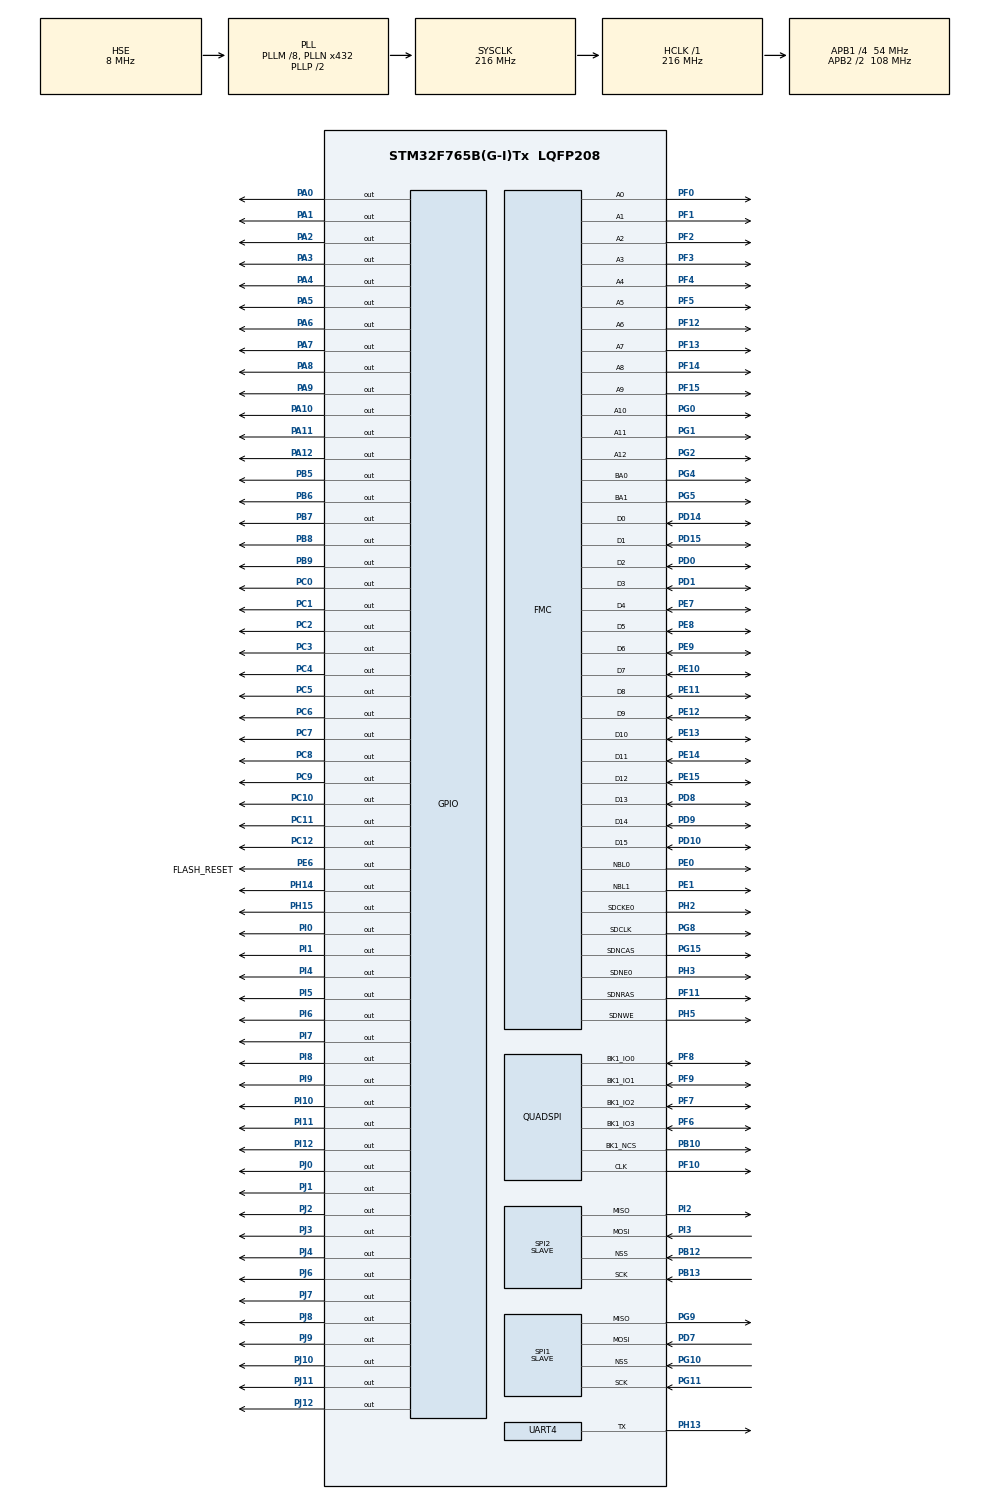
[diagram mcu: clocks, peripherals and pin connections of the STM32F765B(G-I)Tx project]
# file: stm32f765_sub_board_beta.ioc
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CORTEX_M7.ART_ACCLERATOR_ENABLE=1
CORTEX_M7.CPU_DCache=Enabled
CORTEX_M7.CPU_ICache=Enabled
CORTEX_M7.PREFETCH_ENABLE=1
FMC.CASLatency1=FMC_SDRAM_CAS_LATENCY_3
FMC.ColumnBitsNumber1=FMC_SDRAM_COLUMN_BITS_NUM_9
FMC.ExitSelfRefreshDelay1=8
FMC.LoadToActiveDelay1=2
FMC.RCDDelay1=2
FMC.RPDelay1=2
FMC.RPDelay2=2
FMC.ReadBurst1=FMC_SDRAM_RBURST_ENABLE
FMC.ReadBurst2=FMC_SDRAM_RBURST_ENABLE
FMC.ReadPipeDelay1=FMC_SDRAM_RPIPE_DELAY_1
FMC.ReadPipeDelay2=FMC_SDRAM_RPIPE_DELAY_1
FMC.RowCycleDelay1=6
FMC.RowCycleDelay2=6
FMC.SDClockPeriod1=FMC_SDRAM_CLOCK_PERIOD_2
FMC.SDClockPeriod2=FMC_SDRAM_CLOCK_PERIOD_2
FMC.SelfRefreshTime1=6
FMC.WriteProtection1=FMC_SDRAM_WRITE_PROTECTION_DISABLE
FMC.WriteRecoveryTime1=4
Mcu.Family=STM32F7
Mcu.Name=STM32F765B(G-I)Tx
Mcu.Package=LQFP208
NVIC.PriorityGroup=NVIC_PRIORITYGROUP_4
NVIC.SPI1_IRQn=true\:4\:0\:true\:true\:true\:3
NVIC.SPI2_IRQn=true\:2\:0\:true\:true\:true\:1
NVIC.TIM8_TRG_COM_TIM14_IRQn=true\:14\:0\:true\:true\:true\:4
NVIC.UART4_IRQn=true\:6\:0\:true\:true\:true\:2
PA0/WKUP.GPIO_ModeDefaultOutputPP=GPIO_MODE_OUTPUT_PP
PA0/WKUP.GPIO_PuPd=GPIO_NOPULL
PA0/WKUP.GPIO_Speed=GPIO_SPEED_FREQ_VERY_HIGH
PA0/WKUP.PinState=GPIO_PIN_RESET
PA0/WKUP.Signal=GPIO_Output
PA1.GPIO_ModeDefaultOutputPP=GPIO_MODE_OUTPUT_PP
PA1.GPIO_PuPd=GPIO_NOPULL
PA1.GPIO_Speed=GPIO_SPEED_FREQ_VERY_HIGH
PA1.PinState=GPIO_PIN_RESET
PA1.Signal=GPIO_Output
PA10.GPIO_ModeDefaultOutputPP=GPIO_MODE_OUTPUT_PP
PA10.GPIO_PuPd=GPIO_NOPULL
PA10.GPIO_Speed=GPIO_SPEED_FREQ_VERY_HIGH
PA10.PinState=GPIO_PIN_RESET
PA10.Signal=GPIO_Output
PA11.GPIO_ModeDefaultOutputPP=GPIO_MODE_OUTPUT_PP
PA11.GPIO_PuPd=GPIO_NOPULL
PA11.GPIO_Speed=GPIO_SPEED_FREQ_VERY_HIGH
PA11.PinState=GPIO_PIN_RESET
PA11.Signal=GPIO_Output
PA12.GPIO_ModeDefaultOutputPP=GPIO_MODE_OUTPUT_PP
PA12.GPIO_PuPd=GPIO_NOPULL
PA12.GPIO_Speed=GPIO_SPEED_FREQ_VERY_HIGH
PA12.PinState=GPIO_PIN_RESET
PA12.Signal=GPIO_Output
PA2.GPIO_ModeDefaultOutputPP=GPIO_MODE_OUTPUT_PP
PA2.GPIO_PuPd=GPIO_NOPULL
PA2.GPIO_Speed=GPIO_SPEED_FREQ_VERY_HIGH
PA2.PinState=GPIO_PIN_RESET
PA2.Signal=GPIO_Output
PA3.GPIO_ModeDefaultOutputPP=GPIO_MODE_OUTPUT_PP
PA3.GPIO_PuPd=GPIO_NOPULL
PA3.GPIO_Speed=GPIO_SPEED_FREQ_VERY_HIGH
PA3.PinState=GPIO_PIN_RESET
PA3.Signal=GPIO_Output
PA4.GPIO_ModeDefaultOutputPP=GPIO_MODE_OUTPUT_PP
PA4.GPIO_PuPd=GPIO_NOPULL
PA4.GPIO_Speed=GPIO_SPEED_FREQ_VERY_HIGH
PA4.PinState=GPIO_PIN_RESET
PA4.Signal=GPIO_Output
PA5.GPIO_ModeDefaultOutputPP=GPIO_MODE_OUTPUT_PP
PA5.GPIO_PuPd=GPIO_NOPULL
PA5.GPIO_Speed=GPIO_SPEED_FREQ_VERY_HIGH
PA5.PinState=GPIO_PIN_RESET
PA5.Signal=GPIO_Output
PA6.GPIO_ModeDefaultOutputPP=GPIO_MODE_OUTPUT_PP
PA6.GPIO_PuPd=GPIO_NOPULL
PA6.GPIO_Speed=GPIO_SPEED_FREQ_VERY_HIGH
PA6.PinState=GPIO_PIN_RESET
PA6.Signal=GPIO_Output
PA7.GPIO_ModeDefaultOutputPP=GPIO_MODE_OUTPUT_PP
PA7.GPIO_PuPd=GPIO_NOPULL
PA7.GPIO_Speed=GPIO_SPEED_FREQ_VERY_HIGH
PA7.PinState=GPIO_PIN_RESET
PA7.Signal=GPIO_Output
PA8.GPIO_ModeDefaultOutputPP=GPIO_MODE_OUTPUT_PP
PA8.GPIO_PuPd=GPIO_NOPULL
PA8.GPIO_Speed=GPIO_SPEED_FREQ_VERY_HIGH
PA8.PinState=GPIO_PIN_RESET
PA8.Signal=GPIO_Output
PA9.GPIO_ModeDefaultOutputPP=GPIO_MODE_OUTPUT_PP
PA9.GPIO_PuPd=GPIO_NOPULL
PA9.GPIO_Speed=GPIO_SPEED_FREQ_VERY_HIGH
PA9.PinState=GPIO_PIN_RESET
PA9.Signal=GPIO_Output
PB10.Mode=Single Bank 1
PB10.Signal=QUADSPI_BK1_NCS
PB12.Mode=NSS_Signal_Hard_Input
PB12.Signal=SPI2_NSS
PB13.Mode=Full_Duplex_Slave
PB13.Signal=SPI2_SCK
PB5.GPIO_ModeDefaultOutputPP=GPIO_MODE_OUTPUT_PP
PB5.GPIO_PuPd=GPIO_NOPULL
PB5.GPIO_Speed=GPIO_SPEED_FREQ_VERY_HIGH
PB5.PinState=GPIO_PIN_RESET
PB5.Signal=GPIO_Output
PB6.GPIO_FM6=SYSCFG_PMC_I2C_PB6_FMP
PB6.GPIO_ModeDefaultOutputPP=GPIO_MODE_OUTPUT_PP
PB6.GPIO_PuPd=GPIO_NOPULL
PB6.GPIO_Speed=GPIO_SPEED_FREQ_VERY_HIGH
PB6.PinState=GPIO_PIN_RESET
PB6.Signal=GPIO_Output
PB7.GPIO_FM7=SYSCFG_PMC_I2C_PB7_FMP
PB7.GPIO_ModeDefaultOutputPP=GPIO_MODE_OUTPUT_PP
PB7.GPIO_PuPd=GPIO_NOPULL
PB7.GPIO_Speed=GPIO_SPEED_FREQ_VERY_HIGH
PB7.PinState=GPIO_PIN_RESET
PB7.Signal=GPIO_Output
PB8.GPIO_FM8=SYSCFG_PMC_I2C_PB8_FMP
PB8.GPIO_ModeDefaultOutputPP=GPIO_MODE_OUTPUT_PP
PB8.GPIO_PuPd=GPIO_NOPULL
PB8.GPIO_Speed=GPIO_SPEED_FREQ_VERY_HIGH
PB8.PinState=GPIO_PIN_RESET
PB8.Signal=GPIO_Output
PB9.GPIO_FM9=SYSCFG_PMC_I2C_PB9_FMP
PB9.GPIO_ModeDefaultOutputPP=GPIO_MODE_OUTPUT_PP
PB9.GPIO_PuPd=GPIO_NOPULL
PB9.GPIO_Speed=GPIO_SPEED_FREQ_VERY_HIGH
PB9.PinState=GPIO_PIN_RESET
PB9.Signal=GPIO_Output
PC0.GPIO_ModeDefaultOutputPP=GPIO_MODE_OUTPUT_PP
PC0.GPIO_PuPd=GPIO_NOPULL
PC0.GPIO_Speed=GPIO_SPEED_FREQ_VERY_HIGH
PC0.PinState=GPIO_PIN_RESET
PC0.Signal=GPIO_Output
PC1.GPIO_ModeDefaultOutputPP=GPIO_MODE_OUTPUT_PP
PC1.GPIO_PuPd=GPIO_NOPULL
PC1.GPIO_Speed=GPIO_SPEED_FREQ_VERY_HIGH
PC1.PinState=GPIO_PIN_RESET
PC1.Signal=GPIO_Output
PC10.GPIO_ModeDefaultOutputPP=GPIO_MODE_OUTPUT_PP
PC10.GPIO_PuPd=GPIO_NOPULL
PC10.GPIO_Speed=GPIO_SPEED_FREQ_VERY_HIGH
PC10.PinState=GPIO_PIN_RESET
PC10.Signal=GPIO_Output
PC11.GPIO_ModeDefaultOutputPP=GPIO_MODE_OUTPUT_PP
PC11.GPIO_PuPd=GPIO_NOPULL
PC11.GPIO_Speed=GPIO_SPEED_FREQ_VERY_HIGH
PC11.PinState=GPIO_PIN_RESET
PC11.Signal=GPIO_Output
PC12.GPIO_ModeDefaultOutputPP=GPIO_MODE_OUTPUT_PP
PC12.GPIO_PuPd=GPIO_NOPULL
PC12.GPIO_Speed=GPIO_SPEED_FREQ_VERY_HIGH
PC12.PinState=GPIO_PIN_RESET
PC12.Signal=GPIO_Output
PC2.GPIO_ModeDefaultOutputPP=GPIO_MODE_OUTPUT_PP
PC2.GPIO_PuPd=GPIO_NOPULL
PC2.GPIO_Speed=GPIO_SPEED_FREQ_VERY_HIGH
PC2.PinState=GPIO_PIN_RESET
PC2.Signal=GPIO_Output
PC3.GPIO_ModeDefaultOutputPP=GPIO_MODE_OUTPUT_PP
PC3.GPIO_PuPd=GPIO_NOPULL
PC3.GPIO_Speed=GPIO_SPEED_FREQ_VERY_HIGH
PC3.PinState=GPIO_PIN_RESET
PC3.Signal=GPIO_Output
PC4.GPIO_ModeDefaultOutputPP=GPIO_MODE_OUTPUT_PP
PC4.GPIO_PuPd=GPIO_NOPULL
PC4.GPIO_Speed=GPIO_SPEED_FREQ_VERY_HIGH
PC4.PinState=GPIO_PIN_RESET
PC4.Signal=GPIO_Output
PC5.GPIO_ModeDefaultOutputPP=GPIO_MODE_OUTPUT_PP
PC5.GPIO_PuPd=GPIO_NOPULL
PC5.GPIO_Speed=GPIO_SPEED_FREQ_VERY_HIGH
PC5.PinState=GPIO_PIN_RESET
PC5.Signal=GPIO_Output
PC6.GPIO_ModeDefaultOutputPP=GPIO_MODE_OUTPUT_PP
PC6.GPIO_PuPd=GPIO_NOPULL
PC6.GPIO_Speed=GPIO_SPEED_FREQ_VERY_HIGH
PC6.PinState=GPIO_PIN_RESET
PC6.Signal=GPIO_Output
PC7.GPIO_ModeDefaultOutputPP=GPIO_MODE_OUTPUT_PP
PC7.GPIO_PuPd=GPIO_NOPULL
PC7.GPIO_Speed=GPIO_SPEED_FREQ_VERY_HIGH
PC7.PinState=GPIO_PIN_RESET
PC7.Signal=GPIO_Output
PC8.GPIO_ModeDefaultOutputPP=GPIO_MODE_OUTPUT_PP
PC8.GPIO_PuPd=GPIO_NOPULL
PC8.GPIO_Speed=GPIO_SPEED_FREQ_VERY_HIGH
PC8.PinState=GPIO_PIN_RESET
PC8.Signal=GPIO_Output
PC9.GPIO_ModeDefaultOutputPP=GPIO_MODE_OUTPUT_PP
PC9.GPIO_PuPd=GPIO_NOPULL
PC9.GPIO_Speed=GPIO_SPEED_FREQ_VERY_HIGH
PC9.PinState=GPIO_PIN_RESET
PC9.Signal=GPIO_Output
PD0.Signal=FMC_D2_DA2
PD1.Signal=FMC_D3_DA3
PD10.Signal=FMC_D15_DA15
PD14.Signal=FMC_D0_DA0
PD15.Signal=FMC_D1_DA1
PD7.Mode=Full_Duplex_Slave
PD7.Signal=SPI1_MOSI
PD8.Signal=FMC_D13_DA13
PD9.Signal=FMC_D14_DA14
PE0.Signal=FMC_NBL0
PE1.Signal=FMC_NBL1
PE10.Signal=FMC_D7_DA7
PE11.Signal=FMC_D8_DA8
PE12.Signal=FMC_D9_DA9
PE13.Signal=FMC_D10_DA10
PE14.Signal=FMC_D11_DA11
PE15.Signal=FMC_D12_DA12
PE6.GPIO_Label=FLASH_RESET
PE6.GPIO_ModeDefaultOutputPP=GPIO_MODE_OUTPUT_PP
PE6.GPIO_PuPd=GPIO_NOPULL
PE6.GPIO_Speed=GPIO_SPEED_FREQ_VERY_HIGH
PE6.PinState=GPIO_PIN_RESET
PE6.Signal=GPIO_Output
PE7.Signal=FMC_D4_DA4
PE8.Signal=FMC_D5_DA5
PE9.Signal=FMC_D6_DA6
PF0.Signal=FMC_A0
PF1.Signal=FMC_A1
PF10.Mode=Single Bank 1
PF10.Signal=QUADSPI_CLK
PF11.Signal=FMC_SDNRAS
PF12.Signal=FMC_A6
PF13.Signal=FMC_A7
PF14.Signal=FMC_A8
PF15.Signal=FMC_A9
PF2.Signal=FMC_A2
PF3.Signal=FMC_A3
PF4.Signal=FMC_A4
PF5.Signal=FMC_A5
PF6.Mode=Single Bank 1
PF6.Signal=QUADSPI_BK1_IO3
PF7.Mode=Single Bank 1
PF7.Signal=QUADSPI_BK1_IO2
PF8.Mode=Single Bank 1
PF8.Signal=QUADSPI_BK1_IO0
PF9.Mode=Single Bank 1
PF9.Signal=QUADSPI_BK1_IO1
PG0.Signal=FMC_A10
PG1.Signal=FMC_A11
PG10.Mode=NSS_Signal_Hard_Input
PG10.Signal=SPI1_NSS
PG11.Mode=Full_Duplex_Slave
PG11.Signal=SPI1_SCK
PG15.Signal=FMC_SDNCAS
PG2.Signal=FMC_A12
PG4.Signal=FMC_A14_BA0
PG5.Signal=FMC_A15_BA1
PG8.Signal=FMC_SDCLK
PG9.Mode=Full_Duplex_Slave
PG9.Signal=SPI1_MISO
PH0/OSC_IN.Mode=HSE-External-Oscillator
PH0/OSC_IN.Signal=RCC_OSC_IN
PH1/OSC_OUT.Mode=HSE-External-Oscillator
PH1/OSC_OUT.Signal=RCC_OSC_OUT
PH13.Mode=Half_duplex(single_wire_mode)
PH13.Signal=UART4_TX
PH14.GPIO_ModeDefaultOutputPP=GPIO_MODE_OUTPUT_PP
PH14.GPIO_PuPd=GPIO_NOPULL
PH14.GPIO_Speed=GPIO_SPEED_FREQ_VERY_HIGH
PH14.PinState=GPIO_PIN_RESET
PH14.Signal=GPIO_Output
PH15.GPIO_ModeDefaultOutputPP=GPIO_MODE_OUTPUT_PP
PH15.GPIO_PuPd=GPIO_NOPULL
PH15.GPIO_Speed=GPIO_SPEED_FREQ_VERY_HIGH
PH15.PinState=GPIO_PIN_RESET
PH15.Signal=GPIO_Output
PH2.Mode=SdramChipSelect1_1
PH2.Signal=FMC_SDCKE0
PH3.Mode=SdramChipSelect1_1
PH3.Signal=FMC_SDNE0
PH5.Signal=FMC_SDNWE
PI0.GPIO_ModeDefaultOutputPP=GPIO_MODE_OUTPUT_PP
PI0.GPIO_PuPd=GPIO_NOPULL
PI0.GPIO_Speed=GPIO_SPEED_FREQ_VERY_HIGH
PI0.PinState=GPIO_PIN_RESET
PI0.Signal=GPIO_Output
PI1.GPIO_ModeDefaultOutputPP=GPIO_MODE_OUTPUT_PP
PI1.GPIO_PuPd=GPIO_NOPULL
PI1.GPIO_Speed=GPIO_SPEED_FREQ_VERY_HIGH
PI1.PinState=GPIO_PIN_RESET
PI1.Signal=GPIO_Output
PI10.GPIO_ModeDefaultOutputPP=GPIO_MODE_OUTPUT_PP
PI10.GPIO_PuPd=GPIO_NOPULL
PI10.GPIO_Speed=GPIO_SPEED_FREQ_VERY_HIGH
PI10.PinState=GPIO_PIN_RESET
PI10.Signal=GPIO_Output
PI11.GPIO_ModeDefaultOutputPP=GPIO_MODE_OUTPUT_PP
PI11.GPIO_PuPd=GPIO_NOPULL
PI11.GPIO_Speed=GPIO_SPEED_FREQ_VERY_HIGH
PI11.PinState=GPIO_PIN_RESET
PI11.Signal=GPIO_Output
PI12.GPIO_ModeDefaultOutputPP=GPIO_MODE_OUTPUT_PP
PI12.GPIO_PuPd=GPIO_NOPULL
PI12.GPIO_Speed=GPIO_SPEED_FREQ_VERY_HIGH
PI12.PinState=GPIO_PIN_RESET
PI12.Signal=GPIO_Output
PI2.Mode=Full_Duplex_Slave
PI2.Signal=SPI2_MISO
PI3.Mode=Full_Duplex_Slave
PI3.Signal=SPI2_MOSI
PI4.GPIO_ModeDefaultOutputPP=GPIO_MODE_OUTPUT_PP
PI4.GPIO_PuPd=GPIO_NOPULL
PI4.GPIO_Speed=GPIO_SPEED_FREQ_VERY_HIGH
PI4.PinState=GPIO_PIN_RESET
PI4.Signal=GPIO_Output
PI5.GPIO_ModeDefaultOutputPP=GPIO_MODE_OUTPUT_PP
PI5.GPIO_PuPd=GPIO_NOPULL
PI5.GPIO_Speed=GPIO_SPEED_FREQ_VERY_HIGH
PI5.PinState=GPIO_PIN_RESET
PI5.Signal=GPIO_Output
PI6.GPIO_ModeDefaultOutputPP=GPIO_MODE_OUTPUT_PP
PI6.GPIO_PuPd=GPIO_NOPULL
PI6.GPIO_Speed=GPIO_SPEED_FREQ_VERY_HIGH
PI6.PinState=GPIO_PIN_RESET
PI6.Signal=GPIO_Output
PI7.GPIO_ModeDefaultOutputPP=GPIO_MODE_OUTPUT_PP
PI7.GPIO_PuPd=GPIO_NOPULL
PI7.GPIO_Speed=GPIO_SPEED_FREQ_VERY_HIGH
PI7.PinState=GPIO_PIN_RESET
PI7.Signal=GPIO_Output
PI8.GPIO_ModeDefaultOutputPP=GPIO_MODE_OUTPUT_PP
PI8.GPIO_PuPd=GPIO_NOPULL
PI8.GPIO_Speed=GPIO_SPEED_FREQ_LOW
PI8.PinState=GPIO_PIN_RESET
PI8.Signal=GPIO_Output
PI9.GPIO_ModeDefaultOutputPP=GPIO_MODE_OUTPUT_PP
PI9.GPIO_PuPd=GPIO_NOPULL
PI9.GPIO_Speed=GPIO_SPEED_FREQ_VERY_HIGH
PI9.PinState=GPIO_PIN_RESET
PI9.Signal=GPIO_Output
PJ0.GPIO_ModeDefaultOutputPP=GPIO_MODE_OUTPUT_PP
PJ0.GPIO_PuPd=GPIO_NOPULL
PJ0.GPIO_Speed=GPIO_SPEED_FREQ_VERY_HIGH
PJ0.PinState=GPIO_PIN_RESET
PJ0.Signal=GPIO_Output
PJ1.GPIO_ModeDefaultOutputPP=GPIO_MODE_OUTPUT_PP
PJ1.GPIO_PuPd=GPIO_NOPULL
PJ1.GPIO_Speed=GPIO_SPEED_FREQ_VERY_HIGH
PJ1.PinState=GPIO_PIN_RESET
PJ1.Signal=GPIO_Output
PJ10.GPIO_ModeDefaultOutputPP=GPIO_MODE_OUTPUT_PP
PJ10.GPIO_PuPd=GPIO_NOPULL
PJ10.GPIO_Speed=GPIO_SPEED_FREQ_VERY_HIGH
PJ10.PinState=GPIO_PIN_RESET
PJ10.Signal=GPIO_Output
PJ11.GPIO_ModeDefaultOutputPP=GPIO_MODE_OUTPUT_PP
PJ11.GPIO_PuPd=GPIO_NOPULL
PJ11.GPIO_Speed=GPIO_SPEED_FREQ_VERY_HIGH
PJ11.PinState=GPIO_PIN_RESET
PJ11.Signal=GPIO_Output
PJ12.GPIO_ModeDefaultOutputPP=GPIO_MODE_OUTPUT_PP
PJ12.GPIO_PuPd=GPIO_NOPULL
PJ12.GPIO_Speed=GPIO_SPEED_FREQ_VERY_HIGH
PJ12.PinState=GPIO_PIN_RESET
PJ12.Signal=GPIO_Output
PJ2.GPIO_ModeDefaultOutputPP=GPIO_MODE_OUTPUT_PP
PJ2.GPIO_PuPd=GPIO_NOPULL
PJ2.GPIO_Speed=GPIO_SPEED_FREQ_VERY_HIGH
PJ2.PinState=GPIO_PIN_RESET
PJ2.Signal=GPIO_Output
PJ3.GPIO_ModeDefaultOutputPP=GPIO_MODE_OUTPUT_PP
PJ3.GPIO_PuPd=GPIO_NOPULL
PJ3.GPIO_Speed=GPIO_SPEED_FREQ_VERY_HIGH
PJ3.PinState=GPIO_PIN_RESET
PJ3.Signal=GPIO_Output
PJ4.GPIO_ModeDefaultOutputPP=GPIO_MODE_OUTPUT_PP
PJ4.GPIO_PuPd=GPIO_NOPULL
PJ4.GPIO_Speed=GPIO_SPEED_FREQ_VERY_HIGH
PJ4.PinState=GPIO_PIN_RESET
PJ4.Signal=GPIO_Output
PJ6.GPIO_ModeDefaultOutputPP=GPIO_MODE_OUTPUT_PP
PJ6.GPIO_PuPd=GPIO_NOPULL
PJ6.GPIO_Speed=GPIO_SPEED_FREQ_VERY_HIGH
PJ6.PinState=GPIO_PIN_RESET
PJ6.Signal=GPIO_Output
PJ7.GPIO_ModeDefaultOutputPP=GPIO_MODE_OUTPUT_PP
PJ7.GPIO_PuPd=GPIO_NOPULL
PJ7.GPIO_Speed=GPIO_SPEED_FREQ_VERY_HIGH
PJ7.PinState=GPIO_PIN_RESET
PJ7.Signal=GPIO_Output
PJ8.GPIO_ModeDefaultOutputPP=GPIO_MODE_OUTPUT_PP
PJ8.GPIO_PuPd=GPIO_NOPULL
PJ8.GPIO_Speed=GPIO_SPEED_FREQ_VERY_HIGH
PJ8.PinState=GPIO_PIN_RESET
PJ8.Signal=GPIO_Output
PJ9.GPIO_ModeDefaultOutputPP=GPIO_MODE_OUTPUT_PP
PJ9.GPIO_PuPd=GPIO_NOPULL
PJ9.GPIO_Speed=GPIO_SPEED_FREQ_VERY_HIGH
PJ9.PinState=GPIO_PIN_RESET
PJ9.Signal=GPIO_Output
ProjectManager.HeapSize=0x400
ProjectManager.StackSize=0x800
ProjectManager.TargetToolchain=MDK-ARM V5
QUADSPI.ChipSelectHighTime=QSPI_CS_HIGH_TIME_4_CYCLE
QUADSPI.ClockPrescaler=2
QUADSPI.FifoThreshold=8
QUADSPI.FlashSize=26
QUADSPI.SampleShifting=QSPI_SAMPLE_SHIFTING_HALFCYCLE
RCC.AHBFreq_Value=216000000
RCC.APB1CLKDivider=RCC_HCLK_DIV4
RCC.APB1Freq_Value=54000000
RCC.APB1TimFreq_Value=108000000
RCC.APB2CLKDivider=RCC_HCLK_DIV2
RCC.APB2Freq_Value=108000000
RCC.APB2TimFreq_Value=216000000
RCC.CortexFreq_Value=216000000
RCC.EnbaleCSS=true
RCC.HCLKFreq_Value=216000000
RCC.HSE_VALUE=8000000
RCC.HSI_VALUE=16000000
RCC.LSE_VALUE=32768
RCC.PLLM=8
RCC.PLLN=432
RCC.PLLSourceVirtual=RCC_PLLSOURCE_HSE
RCC.SYSCLKFreq_VALUE=216000000
RCC.SYSCLKSource=RCC_SYSCLKSOURCE_PLLCLK
RCC.UART4CLockSelection=RCC_UART4CLKSOURCE_SYSCLK
RCC.USBFreq_Value=216000000
RCC.VCOOutputFreq_Value=432000000
SH.FMC_A0.0=FMC_A0,13b-sda1
SH.FMC_A1.0=FMC_A1,13b-sda1
SH.FMC_A10.0=FMC_A10,13b-sda1
SH.FMC_A11.0=FMC_A11,13b-sda1
SH.FMC_A12.0=FMC_A12,13b-sda1
SH.FMC_A14_BA0.0=FMC_BA0,FourSdramBanks1
SH.FMC_A15_BA1.0=FMC_BA1,FourSdramBanks1
SH.FMC_A2.0=FMC_A2,13b-sda1
SH.FMC_A3.0=FMC_A3,13b-sda1
SH.FMC_A4.0=FMC_A4,13b-sda1
SH.FMC_A5.0=FMC_A5,13b-sda1
SH.FMC_A6.0=FMC_A6,13b-sda1
SH.FMC_A7.0=FMC_A7,13b-sda1
SH.FMC_A8.0=FMC_A8,13b-sda1
SH.FMC_A9.0=FMC_A9,13b-sda1
SH.FMC_D0_DA0.0=FMC_D0,sd-16b-d1
SH.FMC_D10_DA10.0=FMC_D10,sd-16b-d1
SH.FMC_D11_DA11.0=FMC_D11,sd-16b-d1
SH.FMC_D12_DA12.0=FMC_D12,sd-16b-d1
SH.FMC_D13_DA13.0=FMC_D13,sd-16b-d1
SH.FMC_D14_DA14.0=FMC_D14,sd-16b-d1
SH.FMC_D15_DA15.0=FMC_D15,sd-16b-d1
SH.FMC_D1_DA1.0=FMC_D1,sd-16b-d1
SH.FMC_D2_DA2.0=FMC_D2,sd-16b-d1
SH.FMC_D3_DA3.0=FMC_D3,sd-16b-d1
SH.FMC_D4_DA4.0=FMC_D4,sd-16b-d1
SH.FMC_D5_DA5.0=FMC_D5,sd-16b-d1
SH.FMC_D6_DA6.0=FMC_D6,sd-16b-d1
SH.FMC_D7_DA7.0=FMC_D7,sd-16b-d1
SH.FMC_D8_DA8.0=FMC_D8,sd-16b-d1
SH.FMC_D9_DA9.0=FMC_D9,sd-16b-d1
SH.FMC_NBL0.0=FMC_NBL0,Sd2ByteEnable1
SH.FMC_NBL1.0=FMC_NBL1,Sd2ByteEnable1
SH.FMC_SDCLK.0=FMC_SDCLK,13b-sda1
SH.FMC_SDNCAS.0=FMC_SDNCAS,13b-sda1
SH.FMC_SDNRAS.0=FMC_SDNRAS,13b-sda1
SH.FMC_SDNWE.0=FMC_SDNWE,13b-sda1
SPI1.CLKPhase=SPI_PHASE_2EDGE
SPI1.CLKPolarity=SPI_POLARITY_HIGH
SPI1.DataSize=SPI_DATASIZE_8BIT
SPI1.Direction=SPI_DIRECTION_2LINES
SPI1.Mode=SPI_MODE_SLAVE
SPI1.TIMode=SPI_TIMODE_DISABLE
SPI1.VirtualNSS=VM_NSSHARD
SPI1.VirtualType=VM_SLAVE
SPI2.CLKPhase=SPI_PHASE_2EDGE
SPI2.CLKPolarity=SPI_POLARITY_HIGH
SPI2.DataSize=SPI_DATASIZE_8BIT
SPI2.Direction=SPI_DIRECTION_2LINES
SPI2.Mode=SPI_MODE_SLAVE
SPI2.VirtualNSS=VM_NSSHARD
SPI2.VirtualType=VM_SLAVE
TIM14.AutoReloadPreload=TIM_AUTORELOAD_PRELOAD_ENABLE
TIM14.ClockDivision=TIM_CLOCKDIVISION_DIV2
TIM14.Period=5000
TIM14.Prescaler=10799
UART4.BaudRate=460800
UART4.DMADisableonRxErrorParam=UART_ADVFEATURE_DMA_DISABLEONRXERROR
UART4.Mode=MODE_TX
UART4.WordLength=WORDLENGTH_8B
VP_TIM14_VS_ClockSourceINT.Mode=Enable_Timer
board=stm32f765_sub_board_beta

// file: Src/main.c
/**
  ******************************************************************************
  * File Name          : main.c
  * Description        : Main program body
  ******************************************************************************
  ** This notice applies to any and all portions of this file
  * that are not between comment pairs USER CODE BEGIN and
  * USER CODE END. Other portions of this file, whether
  * inserted by the user or by software development tools
  * are owned by their respective copyright owners.
  *
  * COPYRIGHT(c) 2017 STMicroelectronics
  *
  * Redistribution and use in source and binary forms, with or without modification,
  * are permitted provided that the following conditions are met:
  *   1. Redistributions of source code must retain the above copyright notice,
  *      this list of conditions and the following disclaimer.
  *   2. Redistributions in binary form must reproduce the above copyright notice,
  *      this list of conditions and the following disclaimer in the documentation
  *      and/or other materials provided with the distribution.
  *   3. Neither the name of STMicroelectronics nor the names of its contributors
  *      may be used to endorse or promote products derived from this software
  *      without specific prior written permission.
  *
  * THIS SOFTWARE IS PROVIDED BY THE COPYRIGHT HOLDERS AND CONTRIBUTORS "AS IS"
  * AND ANY EXPRESS OR IMPLIED WARRANTIES, INCLUDING, BUT NOT LIMITED TO, THE
  * IMPLIED WARRANTIES OF MERCHANTABILITY AND FITNESS FOR A PARTICULAR PURPOSE ARE
  * DISCLAIMED. IN NO EVENT SHALL THE COPYRIGHT HOLDER OR CONTRIBUTORS BE LIABLE
  * FOR ANY DIRECT, INDIRECT, INCIDENTAL, SPECIAL, EXEMPLARY, OR CONSEQUENTIAL
  * DAMAGES (INCLUDING, BUT NOT LIMITED TO, PROCUREMENT OF SUBSTITUTE GOODS OR
  * SERVICES; LOSS OF USE, DATA, OR PROFITS; OR BUSINESS INTERRUPTION) HOWEVER
  * CAUSED AND ON ANY THEORY OF LIABILITY, WHETHER IN CONTRACT, STRICT LIABILITY,
  * OR TORT (INCLUDING NEGLIGENCE OR OTHERWISE) ARISING IN ANY WAY OUT OF THE USE
  * OF THIS SOFTWARE, EVEN IF ADVISED OF THE POSSIBILITY OF SUCH DAMAGE.
  *
  ******************************************************************************
  */
#include "main.h"
#include "stm32f7xx_hal.h"
#include "quadspi.h"
#include "spi.h"
#include "tim.h"
#include "usart.h"
#include "gpio.h"
#include "fmc.h"

/* USER CODE BEGIN Includes */
#include "bsp_mt25q.h"
#include "sdram_handle.h"
#include "gpio_handle.h"
#include "cmd_handle.h"
#include "spi_handle.h"
#include "flash_handle.h"
#include "uart.h"
#include "tab.h"

/* USER CODE END Includes */

/* USER CODE BEGIN PV */
/* Private variables ---------------------------------------------------------*/
#ifdef DEBUG
#define DBG_LOG(x) printf x
#else
#define DBG_LOG(x)
#endif
/* USER CODE END PV */

void SystemClock_Config(void);
static void MX_NVIC_Init(void);

/* USER CODE BEGIN PFP */
/* Private function prototypes -----------------------------------------------*/

/* USER CODE END PFP */

/* USER CODE BEGIN 0 */
uint8_t t[384]={5};
uint8_t r[384]=0;
/* USER CODE END 0 */

int main(void)
{

  /* USER CODE BEGIN 1 */
	uint32_t i,j;
	uint32_t a_temp[]={500,1000,2000,4000,8000,16000,31500,51000,63000};
	uint32_t p_temp[]={5625,11250,22500,45000,90000,180000,35500};
  /* USER CODE END 1 */

  /* Enable I-Cache-------------------------------------------------------------*/
  SCB_EnableICache();

  /* Enable D-Cache-------------------------------------------------------------*/
  SCB_EnableDCache();

  /* MCU Configuration----------------------------------------------------------*/

  /* Reset of all peripherals, Initializes the Flash interface and the Systick. */
  HAL_Init();

  /* Configure the system clock */
  SystemClock_Config();

  /* Initialize all configured peripherals */
  MX_GPIO_Init();
  MX_SPI2_Init();
  MX_FMC_Init();
  MX_UART4_Init();
  MX_TIM14_Init();
  MX_QUADSPI_Init();
  MX_SPI1_Init();

  /* Initialize interrupts */
  MX_NVIC_Init();

  /* USER CODE BEGIN 2 */

	#if 1
  SDRAM_Initialization_Sequence(&hsdram1);
  fsmc_sdram_test();
	#endif

	#if 1
	if(QSPI_UserInit() == 0)
	{
		DBG_LOG(("flash init ok\r\n"));
	}
  #endif

  DBG_LOG(("sys init ok\r\n"));

	print_all_address();
	tab_init();

	all_gpio_self_test();
	reset_ctrl_all();
	spi_int_config(&hspi2,spi_rx_isr);
	HAL_Delay(800);

	//flash_write_amplitude();

  /* USER CODE END 2 */

  /* Infinite loop */
  while (1)
  {

	/* USER CODE BEGIN 3 */
//	GPIOH->BSRR = (uint32_t)GPIO_PIN_14;
//	GPIOH->BSRR = (uint32_t)GPIO_PIN_15 << 16;
//  	HAL_Delay(10);

//	GPIOH->BSRR = (uint32_t)GPIO_PIN_14 << 16;
//	GPIOH->BSRR = (uint32_t)GPIO_PIN_15;
	//DBG_LOG(("\r\n"));
	HAL_Delay(500);

  }
  /* USER CODE END 3 */

}

/** System Clock Configuration*/
void SystemClock_Config(void)
{

  RCC_OscInitTypeDef RCC_OscInitStruct;
  RCC_ClkInitTypeDef RCC_ClkInitStruct;
  RCC_PeriphCLKInitTypeDef PeriphClkInitStruct;

    /**Configure the main internal regulator output voltage
    */
  __HAL_RCC_PWR_CLK_ENABLE();

  __HAL_PWR_VOLTAGESCALING_CONFIG(PWR_REGULATOR_VOLTAGE_SCALE1);

    /**Initializes the CPU, AHB and APB busses clocks
    */
  RCC_OscInitStruct.OscillatorType = RCC_OSCILLATORTYPE_HSE;
  RCC_OscInitStruct.HSEState = RCC_HSE_ON;
  RCC_OscInitStruct.PLL.PLLState = RCC_PLL_ON;
  RCC_OscInitStruct.PLL.PLLSource = RCC_PLLSOURCE_HSE;
  RCC_OscInitStruct.PLL.PLLM = 8;
  RCC_OscInitStruct.PLL.PLLN = 432;
  RCC_OscInitStruct.PLL.PLLP = RCC_PLLP_DIV2;
  RCC_OscInitStruct.PLL.PLLQ = 2;
  if (HAL_RCC_OscConfig(&RCC_OscInitStruct) != HAL_OK)
  {
    _Error_Handler(__FILE__, __LINE__);
  }

    /**Activate the Over-Drive mode
    */
  if (HAL_PWREx_EnableOverDrive() != HAL_OK)
  {
    _Error_Handler(__FILE__, __LINE__);
  }

    /**Initializes the CPU, AHB and APB busses clocks
    */
  RCC_ClkInitStruct.ClockType = RCC_CLOCKTYPE_HCLK|RCC_CLOCKTYPE_SYSCLK
                              |RCC_CLOCKTYPE_PCLK1|RCC_CLOCKTYPE_PCLK2;
  RCC_ClkInitStruct.SYSCLKSource = RCC_SYSCLKSOURCE_PLLCLK;
  RCC_ClkInitStruct.AHBCLKDivider = RCC_SYSCLK_DIV1;
  RCC_ClkInitStruct.APB1CLKDivider = RCC_HCLK_DIV4;
  RCC_ClkInitStruct.APB2CLKDivider = RCC_HCLK_DIV2;

  if (HAL_RCC_ClockConfig(&RCC_ClkInitStruct, FLASH_LATENCY_7) != HAL_OK)
  {
    _Error_Handler(__FILE__, __LINE__);
  }

  PeriphClkInitStruct.PeriphClockSelection = RCC_PERIPHCLK_UART4;
  PeriphClkInitStruct.Uart4ClockSelection = RCC_UART4CLKSOURCE_SYSCLK;
  if (HAL_RCCEx_PeriphCLKConfig(&PeriphClkInitStruct) != HAL_OK)
  {
    _Error_Handler(__FILE__, __LINE__);
  }

    /**Enables the Clock Security System
    */
  HAL_RCC_EnableCSS();

    /**Configure the Systick interrupt time
    */
  HAL_SYSTICK_Config(HAL_RCC_GetHCLKFreq()/1000);

    /**Configure the Systick
    */
  HAL_SYSTICK_CLKSourceConfig(SYSTICK_CLKSOURCE_HCLK);

  /* SysTick_IRQn interrupt configuration */
  HAL_NVIC_SetPriority(SysTick_IRQn, 0, 0);
}

/** NVIC Configuration
*/
static void MX_NVIC_Init(void)
{
  /* SPI2_IRQn interrupt configuration */
  HAL_NVIC_SetPriority(SPI2_IRQn, 2, 0);
  HAL_NVIC_EnableIRQ(SPI2_IRQn);
  /* UART4_IRQn interrupt configuration */
  HAL_NVIC_SetPriority(UART4_IRQn, 6, 0);
  HAL_NVIC_EnableIRQ(UART4_IRQn);
  /* SPI1_IRQn interrupt configuration */
  HAL_NVIC_SetPriority(SPI1_IRQn, 4, 0);
  HAL_NVIC_EnableIRQ(SPI1_IRQn);
  /* TIM8_TRG_COM_TIM14_IRQn interrupt configuration */
  HAL_NVIC_SetPriority(TIM8_TRG_COM_TIM14_IRQn, 14, 0);
  HAL_NVIC_EnableIRQ(TIM8_TRG_COM_TIM14_IRQn);
}

void _Error_Handler(char * file, int line)
{
  while(1)
  {
  }
}

/************************ (C) COPYRIGHT STMicroelectronics *****END OF FILE****/
